# STM32F777 register map
File version: 1.6
CPU: CM7 r0p1, little endian, MPU, FPU, 4 interrupt priority bits
Registers are 32-bit, read-write, reset 0x0 unless marked. A register's access mark holds for its fields unless they carry their own. Offsets are from the block's base; [hi:lo] are bit positions; {n}, {i} and the like mark numbered series.

## GPIOD — General-purpose I/Os
Base 0x40020C00
Same registers: GPIOC 0x40020800, GPIOE 0x40021000, GPIOF 0x40021400, GPIOG 0x40021800, GPIOH 0x40021C00, GPIOI 0x40022000, GPIOJ 0x40022400, GPIOK 0x40022800
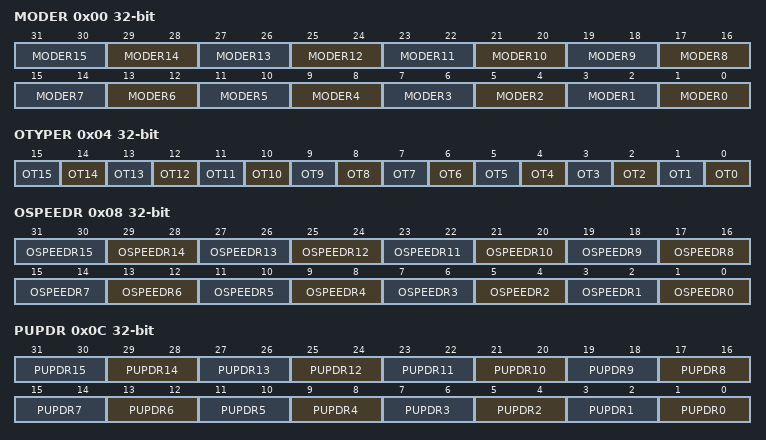
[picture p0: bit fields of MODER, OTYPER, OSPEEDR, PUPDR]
0x00 MODER — GPIO port mode register
  [2n+1:2n] MODER{n} (n=0..15) — Port x configuration pin {n}
    0=Input mode (reset state); 1=Output (General purpose output mode); 2=Alternate function mode; 3=Analog mode
0x04 OTYPER — GPIO port output type register
  [n] OT{n} (n=0..15) — Port x configuration pin {n}
    0=PushPull (Output push-pull (reset state)); 1=OpenDrain (Output open-drain)
0x08 OSPEEDR — GPIO port output speed register
  [2n+1:2n] OSPEEDR{n} (n=0..15) — Port x configuration pin {n}
    0=LowSpeed; 1=MediumSpeed; 2=HighSpeed; 3=VeryHighSpeed
0x0C PUPDR — GPIO port pull-up/pull-down register
  [2n+1:2n] PUPDR{n} (n=0..15) — Port x configuration pin {n}
    0=Floating (No pull-up, pull-down); 1=PullUp; 2=PullDown
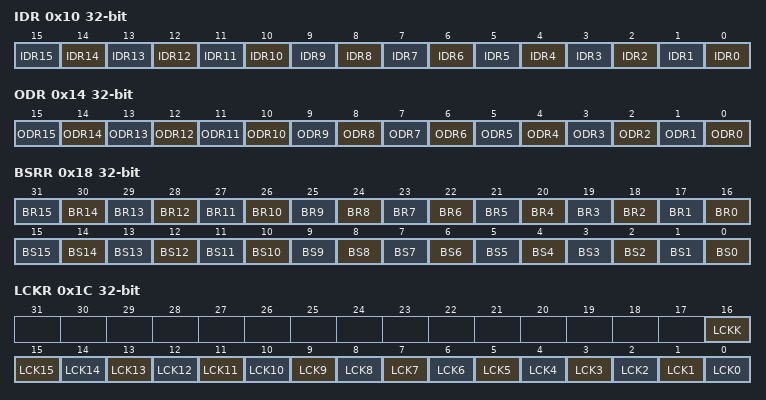
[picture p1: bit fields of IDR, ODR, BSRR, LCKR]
0x10 IDR ro — GPIO port input data register
  [n] IDR{n} (n=0..15) — Port input data pin {n}
    0=Low (Input is logic low); 1=High (Input is logic high)
0x14 ODR — GPIO port output data register
  [n] ODR{n} (n=0..15) — Port output data pin {n}
    0=Low (Set output to logic low); 1=High (Set output to logic high)
0x18 BSRR wo — GPIO port bit set/reset register
  [n+16] BR{n} (n=0..15) — Port x reset pin {n}
    1=Resets the corresponding ODRx bit
  [n] BS{n} (n=0..15) — Port x set pin {n}
    1=Set (Sets the corresponding ODRx bit)
0x1C LCKR — GPIO port configuration lock register
  [16] LCKK — Port x lock bit y (y= 0..15)
    0=NotActive (Port configuration lock key not active); 1=Active (Port configuration lock key active)
  [n] LCK{n} (n=0..15) — Port x lock pin {n}
    0=Unlocked (Port configuration not locked); 1=Locked (Port configuration locked)
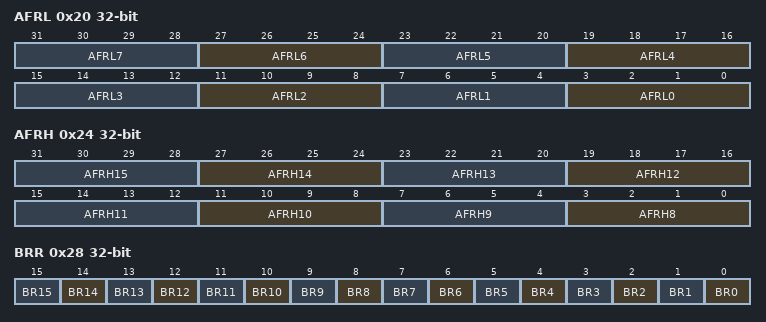
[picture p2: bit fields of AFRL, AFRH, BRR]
0x20 AFRL — GPIO alternate function lowregister
  [3:0] AFR{x} (x=L0,L1,L2,L3,L4,L5,L6,L7; step 4) — Alternate function selection for port x bit y (y = 0..7)
    {v}=AF{v} (v=0..15)
0x24 AFRH — GPIO alternate function high register
  [3:0] AFR{x} (x=H8,H9,H10,H11,H12,H13,H14,H15; step 4) — Alternate function selection for port x bit y (y = 8..15)
    {v}=AF{v} (v=0..15)
0x28 BRR — GPIO port bit reset register
  [n] BR{n} (n=0..15) — Port x reset pin {n}
    on write: 0=No action on the corresponding ODx bit; 1=Reset the ODx bit

## GPIOB — General-purpose I/Os
Base 0x40020400
Registers as GPIOD; these are added or differ:
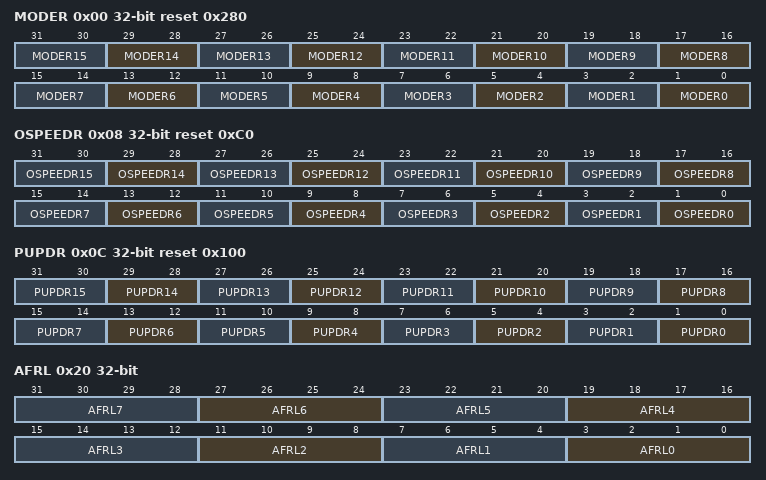
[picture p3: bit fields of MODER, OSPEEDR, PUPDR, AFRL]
0x00 MODER reset 0x280 — GPIO port mode register
  [2n+1:2n] MODER{n} (n=0..15) — Port x configuration pin {n}
    0=Input mode (reset state); 1=Output (General purpose output mode); 2=Alternate function mode; 3=Analog mode
0x08 OSPEEDR reset 0xC0 — GPIO port output speed register
  [2n+1:2n] OSPEEDR{n} (n=0..15) — Port x configuration pin {n}
    0=LowSpeed; 1=MediumSpeed; 2=HighSpeed; 3=VeryHighSpeed
0x0C PUPDR reset 0x100 — GPIO port pull-up/pull-down register
  [2n+1:2n] PUPDR{n} (n=0..15) — Port x configuration pin {n}
    0=Floating (No pull-up, pull-down); 1=PullUp; 2=PullDown
0x20 AFRL — GPIO alternate function low register
  [3:0] AFR{x} (x=L0,L1,L2,L3,L4,L5,L6,L7; step 4) — Alternate function selection for port x bit y (y = 0..7)
    {v}=AF{v} (v=0..15)

## GPIOA — General-purpose I/Os
Base 0x40020000
Registers as GPIOB; these are added or differ:
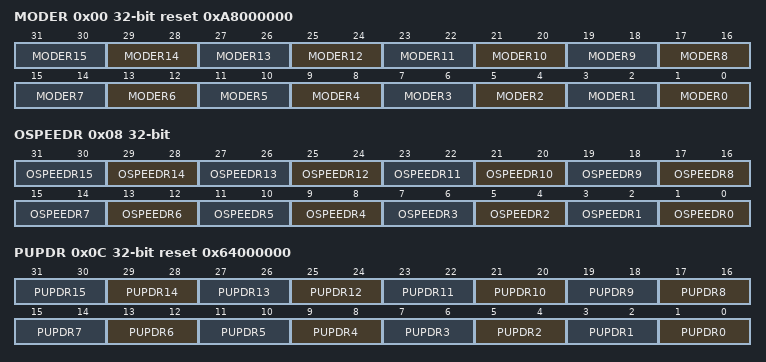
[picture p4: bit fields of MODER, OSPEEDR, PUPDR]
0x00 MODER reset 0xA8000000 — GPIO port mode register
  [2n+1:2n] MODER{n} (n=0..15) — Port x configuration pin {n}
    0=Input mode (reset state); 1=Output (General purpose output mode); 2=Alternate function mode; 3=Analog mode
0x08 OSPEEDR — GPIO port output speed register
  [2n+1:2n] OSPEEDR{n} (n=0..15) — Port x configuration pin {n}
    0=LowSpeed; 1=MediumSpeed; 2=HighSpeed; 3=VeryHighSpeed
0x0C PUPDR reset 0x64000000 — GPIO port pull-up/pull-down register
  [2n+1:2n] PUPDR{n} (n=0..15) — Port x configuration pin {n}
    0=Floating (No pull-up, pull-down); 1=PullUp; 2=PullDown
